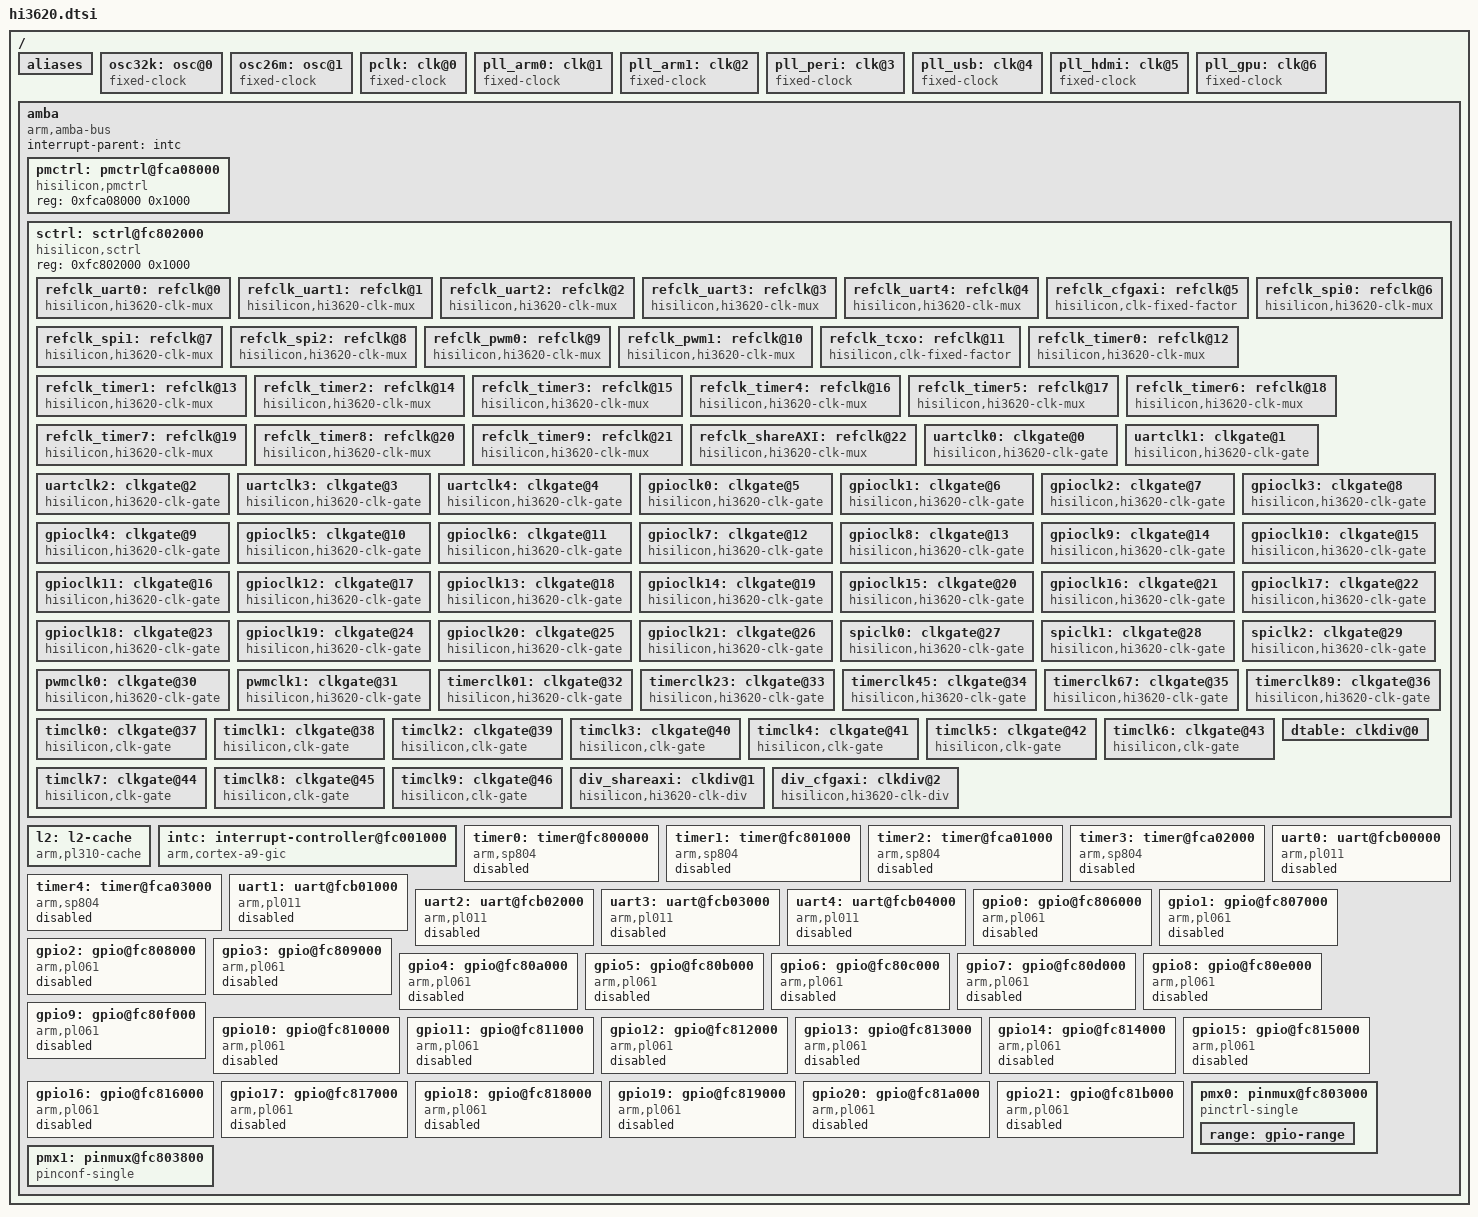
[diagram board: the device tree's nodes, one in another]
/*
 * Hisilicon Ltd. Hi3620 SoC
 *
 * Copyright (C) 2012-2013 Hisilicon Ltd.
 * Copyright (C) 2012-2013 Linaro Ltd.
 *
 * Author: Haojian Zhuang <haojian.zhuang@linaro.org>
 *
 * This program is free software; you can redistribute it and/or modify
 * it under the terms of the GNU General Public License version 2 as
 * publishhed by the Free Software Foundation.
 */

/include/ "skeleton.dtsi"

/ {
	aliases {
		serial0 = &uart0;
		serial1 = &uart1;
		serial2 = &uart2;
		serial3 = &uart3;
		serial4 = &uart4;
	};

	osc32k: osc@0 {
		compatible = "fixed-clock";
		#clock-cells = <0>;
		clock-frequency = <32768>;
		clock-output-names = "osc32khz";
	};
	osc26m: osc@1 {
		compatible = "fixed-clock";
		#clock-cells = <0>;
		clock-frequency = <26000000>;
		clock-output-names = "osc26mhz";
	};
	pclk: clk@0 {
		compatible = "fixed-clock";
		#clock-cells = <0>;
		clock-frequency = <26000000>;
		clock-output-names = "apb_pclk";
	};
	pll_arm0: clk@1 {
		compatible = "fixed-clock";
		#clock-cells = <0>;
		clock-frequency = <1600000000>;
		clock-output-names = "armpll0";
	};
	pll_arm1: clk@2 {
		compatible = "fixed-clock";
		#clock-cells = <0>;
		clock-frequency = <1600000000>;
		clock-output-names = "armpll1";
	};
	pll_peri: clk@3 {
		compatible = "fixed-clock";
		#clock-cells = <0>;
		clock-frequency = <1440000000>;
		clock-output-names = "armpll2";
	};
	pll_usb: clk@4 {
		compatible = "fixed-clock";
		#clock-cells = <0>;
		clock-frequency = <1440000000>;
		clock-output-names = "armpll3";
	};
	pll_hdmi: clk@5 {
		compatible = "fixed-clock";
		#clock-cells = <0>;
		clock-frequency = <1188000000>;
		clock-output-names = "armpll4";
	};
	pll_gpu: clk@6 {
		compatible = "fixed-clock";
		#clock-cells = <0>;
		clock-frequency = <1300000000>;
		clock-output-names = "armpll5";
	};

	amba {
		#address-cells = <1>;
		#size-cells = <1>;
		compatible = "arm,amba-bus";
		interrupt-parent = <&intc>;
		ranges;

		pmctrl: pmctrl@fca08000 {
			compatible = "hisilicon,pmctrl";
			reg = <0xfca08000 0x1000>;
 		};

		sctrl: sctrl@fc802000 {
			compatible = "hisilicon,sctrl";
			reg = <0xfc802000 0x1000>;

			refclk_uart0: refclk@0 {
				compatible = "hisilicon,hi3620-clk-mux";
				#clock-cells = <0>;
				clocks = <&osc26m &pclk>;
				clock-output-names = "rclk_uart0";
				/* each item value */
				/* reg_offset, enable_bits */
				hisilicon,hi3620-clkmux = <0x100 0x80>;
			};
			refclk_uart1: refclk@1 {
				compatible = "hisilicon,hi3620-clk-mux";
				#clock-cells = <0>;
				clocks = <&osc26m &pclk>;
				clock-output-names = "rclk_uart1";
				hisilicon,hi3620-clkmux = <0x100 0x100>;
			};
			refclk_uart2: refclk@2 {
				compatible = "hisilicon,hi3620-clk-mux";
				#clock-cells = <0>;
				clocks = <&osc26m &pclk>;
				clock-output-names = "rclk_uart2";
				hisilicon,hi3620-clkmux = <0x100 0x200>;
			};
			refclk_uart3: refclk@3 {
				compatible = "hisilicon,hi3620-clk-mux";
				#clock-cells = <0>;
				clocks = <&osc26m &pclk>;
				clock-output-names = "rclk_uart3";
				hisilicon,hi3620-clkmux = <0x100 0x400>;
			};
			refclk_uart4: refclk@4 {
				compatible = "hisilicon,hi3620-clk-mux";
				#clock-cells = <0>;
				clocks = <&osc26m &pclk>;
				clock-output-names = "rclk_uart4";
				hisilicon,hi3620-clkmux = <0x100 0x800>;
			};
			refclk_cfgaxi: refclk@5 {
				compatible = "hisilicon,clk-fixed-factor";
				#clock-cells = <0>;
				clocks = <&pll_peri>;
				clock-output-names = "rclk_cfgaxi";
				/*mult, div*/
				hisilicon,fixed-factor = <1 30>;
			};
			refclk_spi0: refclk@6 {
				compatible = "hisilicon,hi3620-clk-mux";
				#clock-cells = <0>;
				clocks = <&osc26m &refclk_cfgaxi>;
				clock-output-names = "rclk_spi0";
				hisilicon,hi3620-clkmux = <0x100 0x1000>;
			};
			refclk_spi1: refclk@7 {
				compatible = "hisilicon,hi3620-clk-mux";
				#clock-cells = <0>;
				clocks = <&osc26m &refclk_cfgaxi>;
				clock-output-names = "rclk_spi1";
				hisilicon,hi3620-clkmux = <0x100 0x2000>;
			};
			refclk_spi2: refclk@8 {
				compatible = "hisilicon,hi3620-clk-mux";
				#clock-cells = <0>;
				clocks = <&osc26m &refclk_cfgaxi>;
				clock-output-names = "rclk_spi2";
				hisilicon,hi3620-clkmux = <0x100 0x4000>;
			};
			refclk_pwm0: refclk@9 {
				compatible = "hisilicon,hi3620-clk-mux";
				#clock-cells = <0>;
				clocks = <&osc32k &osc26m>;
				clock-output-names = "rclk_pwm0";
				hisilicon,hi3620-clkmux = <0x104 0x400>;
			};
			refclk_pwm1: refclk@10 {
				compatible = "hisilicon,hi3620-clk-mux";
				#clock-cells = <0>;
				clocks = <&osc32k &osc26m>;
				clock-output-names = "rclk_pwm1";
				hisilicon,hi3620-clkmux = <0x104 0x800>;
			};
			refclk_tcxo: refclk@11 {
				compatible = "hisilicon,clk-fixed-factor";
				#clock-cells = <0>;
				clocks = <&osc26m>;
				clock-output-names = "rclk_tcxo";
				hisilicon,fixed-factor = <1 4>;
			};
			refclk_timer0: refclk@12 {
				compatible = "hisilicon,hi3620-clk-mux";
				#clock-cells = <0>;
				clocks = <&osc32k &timerclk01>;
				clock-output-names = "rclk_tim0";
				hisilicon,hi3620-clkmux = <0 0x8000>;
			};
			refclk_timer1: refclk@13 {
				compatible = "hisilicon,hi3620-clk-mux";
				#clock-cells = <0>;
				clocks = <&osc32k &timerclk01>;
				clock-output-names = "rclk_tim1";
				hisilicon,hi3620-clkmux = <0 0x20000>;
			};
			refclk_timer2: refclk@14 {
				compatible = "hisilicon,hi3620-clk-mux";
				#clock-cells = <0>;
				clocks = <&osc32k &timerclk23>;
				clock-output-names = "rclk_tim2";
				hisilicon,hi3620-clkmux = <0 0x80000>;
			};
			refclk_timer3: refclk@15 {
				compatible = "hisilicon,hi3620-clk-mux";
				#clock-cells = <0>;
				clocks = <&osc32k &timerclk23>;
				clock-output-names = "rclk_tim3";
				hisilicon,hi3620-clkmux = <0 0x200000>;
			};
			refclk_timer4: refclk@16 {
				compatible = "hisilicon,hi3620-clk-mux";
				#clock-cells = <0>;
				clocks = <&osc32k &timerclk45>;
				clock-output-names = "rclk_tim4";
				hisilicon,hi3620-clkmux = <0x18 0x1>;
			};
			refclk_timer5: refclk@17 {
				compatible = "hisilicon,hi3620-clk-mux";
				#clock-cells = <0>;
				clocks = <&osc32k &timerclk45>;
				clock-output-names = "rclk_tim5";
				hisilicon,hi3620-clkmux = <0x18 0x4>;
			};
			refclk_timer6: refclk@18 {
				compatible = "hisilicon,hi3620-clk-mux";
				#clock-cells = <0>;
				clocks = <&osc32k &timerclk67>;
				clock-output-names = "rclk_tim6";
				hisilicon,hi3620-clkmux = <0x18 0x10>;
			};
			refclk_timer7: refclk@19 {
				compatible = "hisilicon,hi3620-clk-mux";
				#clock-cells = <0>;
				clocks = <&osc32k &timerclk67>;
				clock-output-names = "rclk_tim7";
				hisilicon,hi3620-clkmux = <0x18 0x40>;
			};
			refclk_timer8: refclk@20 {
				compatible = "hisilicon,hi3620-clk-mux";
				#clock-cells = <0>;
				clocks = <&osc32k &timerclk89>;
				clock-output-names = "rclk_tim8";
				hisilicon,hi3620-clkmux = <0x18 0x100>;
			};
			refclk_timer9: refclk@21 {
				compatible = "hisilicon,hi3620-clk-mux";
				#clock-cells = <0>;
				clocks = <&osc32k &timerclk89>;
				clock-output-names = "rclk_tim9";
				hisilicon,hi3620-clkmux = <0x18 0x400>;
			};
			refclk_shareAXI: refclk@22 {
				compatible = "hisilicon,hi3620-clk-mux";
				#clock-cells = <0>;
				clocks = <&pll_usb &pll_peri>;
				clock-output-names = "rclk_shareAXI";
				hisilicon,hi3620-clkmux = <0x24 0x8000>;
			};
			uartclk0: clkgate@0 {
				compatible = "hisilicon,hi3620-clk-gate";
				#clock-cells = <0>;
				clocks = <&refclk_uart0>;
				clock-output-names = "uartclk0";
				hisilicon,hi3620-clkreset = <0x98 0x10000>;
				hisilicon,hi3620-clkgate = <0x40 0x10000>;
			};
			uartclk1: clkgate@1 {
				compatible = "hisilicon,hi3620-clk-gate";
				#clock-cells = <0>;
				clocks = <&refclk_uart1>;
				clock-output-names = "uartclk1";
				hisilicon,hi3620-clkreset = <0x98 0x20000>;
				hisilicon,hi3620-clkgate = <0x40 0x20000>;
			};
			uartclk2: clkgate@2 {
				compatible = "hisilicon,hi3620-clk-gate";
				#clock-cells = <0>;
				clocks = <&refclk_uart2>;
				clock-output-names = "uartclk2";
				hisilicon,hi3620-clkreset = <0x98 0x40000>;
				hisilicon,hi3620-clkgate = <0x40 0x40000>;
			};
			uartclk3: clkgate@3 {
				compatible = "hisilicon,hi3620-clk-gate";
				#clock-cells = <0>;
				clocks = <&refclk_uart3>;
				clock-output-names = "uartclk3";
				hisilicon,hi3620-clkreset = <0x98 0x80000>;
				hisilicon,hi3620-clkgate = <0x40 0x80000>;
			};
			uartclk4: clkgate@4 {
				compatible = "hisilicon,hi3620-clk-gate";
				#clock-cells = <0>;
				clocks = <&refclk_uart4>;
				clock-output-names = "uartclk4";
				hisilicon,hi3620-clkreset = <0x98 0x100000>;
				hisilicon,hi3620-clkgate = <0x40 0x100000>;
			};
			gpioclk0: clkgate@5 {
				compatible = "hisilicon,hi3620-clk-gate";
				#clock-cells = <0>;
				clocks = <&pclk>;
				clock-output-names = "gpioclk0";
				hisilicon,hi3620-clkreset = <0x80 0x100>;
				hisilicon,hi3620-clkgate = <0x20 0x100>;
			};
			gpioclk1: clkgate@6 {
				compatible = "hisilicon,hi3620-clk-gate";
				#clock-cells = <0>;
				clocks = <&pclk>;
				clock-output-names = "gpioclk1";
				hisilicon,hi3620-clkreset = <0x80 0x200>;
				hisilicon,hi3620-clkgate = <0x20 0x200>;
			};
			gpioclk2: clkgate@7 {
				compatible = "hisilicon,hi3620-clk-gate";
				#clock-cells = <0>;
				clocks = <&pclk>;
				clock-output-names = "gpioclk2";
				hisilicon,hi3620-clkreset = <0x80 0x400>;
				hisilicon,hi3620-clkgate = <0x20 0x400>;
			};
			gpioclk3: clkgate@8 {
				compatible = "hisilicon,hi3620-clk-gate";
				#clock-cells = <0>;
				clocks = <&pclk>;
				clock-output-names = "gpioclk3";
				hisilicon,hi3620-clkreset = <0x80 0x800>;
				hisilicon,hi3620-clkgate = <0x20 0x800>;
			};
			gpioclk4: clkgate@9 {
				compatible = "hisilicon,hi3620-clk-gate";
				#clock-cells = <0>;
				clocks = <&pclk>;
				clock-output-names = "gpioclk4";
				hisilicon,hi3620-clkreset = <0x80 0x1000>;
				hisilicon,hi3620-clkgate = <0x20 0x1000>;
			};
			gpioclk5: clkgate@10 {
				compatible = "hisilicon,hi3620-clk-gate";
				#clock-cells = <0>;
				clocks = <&pclk>;
				clock-output-names = "gpioclk5";
				hisilicon,hi3620-clkreset = <0x80 0x2000>;
				hisilicon,hi3620-clkgate = <0x20 0x2000>;
			};
			gpioclk6: clkgate@11 {
				compatible = "hisilicon,hi3620-clk-gate";
				#clock-cells = <0>;
				clocks = <&pclk>;
				clock-output-names = "gpioclk6";
				hisilicon,hi3620-clkreset = <0x80 0x4000>;
				hisilicon,hi3620-clkgate = <0x20 0x4000>;
			};
			gpioclk7: clkgate@12 {
				compatible = "hisilicon,hi3620-clk-gate";
				#clock-cells = <0>;
				clocks = <&pclk>;
				clock-output-names = "gpioclk7";
				hisilicon,hi3620-clkreset = <0x80 0x8000>;
				hisilicon,hi3620-clkgate = <0x20 0x8000>;
			};
			gpioclk8: clkgate@13 {
				compatible = "hisilicon,hi3620-clk-gate";
				#clock-cells = <0>;
				clocks = <&pclk>;
				clock-output-names = "gpioclk8";
				hisilicon,hi3620-clkreset = <0x80 0x10000>;
				hisilicon,hi3620-clkgate = <0x20 0x10000>;
			};
			gpioclk9: clkgate@14 {
				compatible = "hisilicon,hi3620-clk-gate";
				#clock-cells = <0>;
				clocks = <&pclk>;
				clock-output-names = "gpioclk9";
				hisilicon,hi3620-clkreset = <0x80 0x20000>;
				hisilicon,hi3620-clkgate = <0x20 0x20000>;
			};
			gpioclk10: clkgate@15 {
				compatible = "hisilicon,hi3620-clk-gate";
				#clock-cells = <0>;
				clocks = <&pclk>;
				clock-output-names = "gpioclk10";
				hisilicon,hi3620-clkreset = <0x80 0x40000>;
				hisilicon,hi3620-clkgate = <0x20 0x40000>;
			};
			gpioclk11: clkgate@16 {
				compatible = "hisilicon,hi3620-clk-gate";
				#clock-cells = <0>;
				clocks = <&pclk>;
				clock-output-names = "gpioclk11";
				hisilicon,hi3620-clkreset = <0x80 0x80000>;
				hisilicon,hi3620-clkgate = <0x20 0x80000>;
			};
			gpioclk12: clkgate@17 {
				compatible = "hisilicon,hi3620-clk-gate";
				#clock-cells = <0>;
				clocks = <&pclk>;
				clock-output-names = "gpioclk12";
				hisilicon,hi3620-clkreset = <0x80 0x100000>;
				hisilicon,hi3620-clkgate = <0x20 0x100000>;
			};
			gpioclk13: clkgate@18 {
				compatible = "hisilicon,hi3620-clk-gate";
				#clock-cells = <0>;
				clocks = <&pclk>;
				clock-output-names = "gpioclk13";
				hisilicon,hi3620-clkreset = <0x80 0x200000>;
				hisilicon,hi3620-clkgate = <0x20 0x200000>;
			};
			gpioclk14: clkgate@19 {
				compatible = "hisilicon,hi3620-clk-gate";
				#clock-cells = <0>;
				clocks = <&pclk>;
				clock-output-names = "gpioclk14";
				hisilicon,hi3620-clkreset = <0x80 0x400000>;
				hisilicon,hi3620-clkgate = <0x20 0x400000>;
			};
			gpioclk15: clkgate@20 {
				compatible = "hisilicon,hi3620-clk-gate";
				#clock-cells = <0>;
				clocks = <&pclk>;
				clock-output-names = "gpioclk15";
				hisilicon,hi3620-clkreset = <0x80 0x800000>;
				hisilicon,hi3620-clkgate = <0x20 0x800000>;
			};
			gpioclk16: clkgate@21 {
				compatible = "hisilicon,hi3620-clk-gate";
				#clock-cells = <0>;
				clocks = <&pclk>;
				clock-output-names = "gpioclk16";
				hisilicon,hi3620-clkreset = <0x80 0x1000000>;
				hisilicon,hi3620-clkgate = <0x20 0x1000000>;
			};
			gpioclk17: clkgate@22 {
				compatible = "hisilicon,hi3620-clk-gate";
				#clock-cells = <0>;
				clocks = <&pclk>;
				clock-output-names = "gpioclk17";
				hisilicon,hi3620-clkreset = <0x80 0x2000000>;
				hisilicon,hi3620-clkgate = <0x20 0x2000000>;
			};
			gpioclk18: clkgate@23 {
				compatible = "hisilicon,hi3620-clk-gate";
				#clock-cells = <0>;
				clocks = <&pclk>;
				clock-output-names = "gpioclk18";
				hisilicon,hi3620-clkreset = <0x80 0x4000000>;
				hisilicon,hi3620-clkgate = <0x20 0x4000000>;
			};
			gpioclk19: clkgate@24 {
				compatible = "hisilicon,hi3620-clk-gate";
				#clock-cells = <0>;
				clocks = <&pclk>;
				clock-output-names = "gpioclk19";
				hisilicon,hi3620-clkreset = <0x80 0x8000000>;
				hisilicon,hi3620-clkgate = <0x20 0x8000000>;
			};
			gpioclk20: clkgate@25 {
				compatible = "hisilicon,hi3620-clk-gate";
				#clock-cells = <0>;
				clocks = <&pclk>;
				clock-output-names = "gpioclk20";
				hisilicon,hi3620-clkreset = <0x80 0x10000000>;
				hisilicon,hi3620-clkgate = <0x20 0x10000000>;
			};
			gpioclk21: clkgate@26 {
				compatible = "hisilicon,hi3620-clk-gate";
				#clock-cells = <0>;
				clocks = <&pclk>;
				clock-output-names = "gpioclk21";
				hisilicon,hi3620-clkreset = <0x80 0x20000000>;
				hisilicon,hi3620-clkgate = <0x20 0x20000000>;
			};
			spiclk0: clkgate@27 {
				compatible = "hisilicon,hi3620-clk-gate";
				#clock-cells = <0>;
				clocks = <&refclk_spi0>;
				clock-output-names = "spiclk0";
				hisilicon,hi3620-clkreset = <0x98 0x200000>;
				hisilicon,hi3620-clkgate = <0x40 0x200000>;
			};
			spiclk1: clkgate@28 {
				compatible = "hisilicon,hi3620-clk-gate";
				#clock-cells = <0>;
				clocks = <&refclk_spi1>;
				clock-output-names = "spiclk1";
				hisilicon,hi3620-clkreset = <0x98 0x400000>;
				hisilicon,hi3620-clkgate = <0x40 0x400000>;
			};
			spiclk2: clkgate@29 {
				compatible = "hisilicon,hi3620-clk-gate";
				#clock-cells = <0>;
				clocks = <&refclk_spi2>;
				clock-output-names = "spiclk2";
				hisilicon,hi3620-clkreset = <0x98 0x800000>;
				hisilicon,hi3620-clkgate = <0x40 0x800000>;
			};
			pwmclk0: clkgate@30 {
				compatible = "hisilicon,hi3620-clk-gate";
				#clock-cells = <0>;
				clocks = <&refclk_pwm0>;
				clock-output-names = "pwmclk0";
				hisilicon,hi3620-clkreset = <0x98 0x80>;
				hisilicon,hi3620-clkgate = <0x40 0x80>;
			};
			pwmclk1: clkgate@31 {
				compatible = "hisilicon,hi3620-clk-gate";
				#clock-cells = <0>;
				clocks = <&refclk_pwm1>;
				clock-output-names = "pwmclk1";
				hisilicon,hi3620-clkreset = <0x98 0x100>;
				hisilicon,hi3620-clkgate = <0x40 0x100>;
			};
			timerclk01: clkgate@32 {
				compatible = "hisilicon,hi3620-clk-gate";
				#clock-cells = <0>;
				clocks = <&refclk_tcxo>;
				clock-output-names = "timerclk01";
				hisilicon,hi3620-clkreset = <0x80 0x1>;
				hisilicon,hi3620-clkgate = <0x20 0x3>;
			};
			timerclk23: clkgate@33 {
				compatible = "hisilicon,hi3620-clk-gate";
				#clock-cells = <0>;
				clocks = <&refclk_tcxo>;
				clock-output-names = "timerclk23";
				hisilicon,hi3620-clkreset = <0x80 0x2>;
				hisilicon,hi3620-clkgate = <0x20 0xc>;
			};
			timerclk45: clkgate@34 {
				compatible = "hisilicon,hi3620-clk-gate";
				#clock-cells = <0>;
				clocks = <&refclk_tcxo>;
				clock-output-names = "timerclk45";
				hisilicon,hi3620-clkreset = <0x98 0x8>;
				hisilicon,hi3620-clkgate = <0x40 0x8>;
			};
			timerclk67: clkgate@35 {
				compatible = "hisilicon,hi3620-clk-gate";
				#clock-cells = <0>;
				clocks = <&refclk_tcxo>;
				clock-output-names = "timerclk67";
				hisilicon,hi3620-clkreset = <0x98 0x10>;
				hisilicon,hi3620-clkgate = <0x40 0x10>;
			};
			timerclk89: clkgate@36 {
				compatible = "hisilicon,hi3620-clk-gate";
				#clock-cells = <0>;
				clocks = <&refclk_tcxo>;
				clock-output-names = "timerclk89";
				hisilicon,hi3620-clkreset = <0x98 0x20>;
				hisilicon,hi3620-clkgate = <0x40 0x20>;
			};
			timclk0: clkgate@37 {
				compatible = "hisilicon,clk-gate";
				#clock-cells = <0>;
				clocks = <&refclk_timer0>;
				clock-output-names = "timclk0";
				hisilicon,clkgate-inverted;
				hisilicon,clkgate = <0 16>;
			};
			timclk1: clkgate@38 {
				compatible = "hisilicon,clk-gate";
				#clock-cells = <0>;
				clocks = <&refclk_timer1>;
				clock-output-names = "timclk1";
				hisilicon,clkgate-inverted;
				hisilicon,clkgate = <0 18>;
			};
			timclk2: clkgate@39 {
				compatible = "hisilicon,clk-gate";
				#clock-cells = <0>;
				clocks = <&refclk_timer2>;
				clock-output-names = "timclk2";
				hisilicon,clkgate-inverted;
				hisilicon,clkgate = <0 20>;
			};
			timclk3: clkgate@40 {
				compatible = "hisilicon,clk-gate";
				#clock-cells = <0>;
				clocks = <&refclk_timer3>;
				clock-output-names = "timclk3";
				hisilicon,clkgate-inverted;
				hisilicon,clkgate = <0 22>;
			};
			timclk4: clkgate@41 {
				compatible = "hisilicon,clk-gate";
				#clock-cells = <0>;
				clocks = <&refclk_timer4>;
				clock-output-names = "timclk4";
				hisilicon,clkgate-inverted;
				hisilicon,clkgate = <0x18 0>;
			};
			timclk5: clkgate@42 {
				compatible = "hisilicon,clk-gate";
				#clock-cells = <0>;
				clocks = <&refclk_timer5>;
				clock-output-names = "timclk5";
				hisilicon,clkgate-inverted;
				hisilicon,clkgate = <0x18 2>;
			};
			timclk6: clkgate@43 {
				compatible = "hisilicon,clk-gate";
				#clock-cells = <0>;
				clocks = <&refclk_timer6>;
				clock-output-names = "timclk6";
				hisilicon,clkgate-inverted;
				hisilicon,clkgate = <0x18 4>;
			};
			timclk7: clkgate@44 {
				compatible = "hisilicon,clk-gate";
				#clock-cells = <0>;
				clocks = <&refclk_timer7>;
				clock-output-names = "timclk7";
				hisilicon,clkgate-inverted;
				hisilicon,clkgate = <0x18 6>;
			};
			timclk8: clkgate@45 {
				compatible = "hisilicon,clk-gate";
				#clock-cells = <0>;
				clocks = <&refclk_timer8>;
				clock-output-names = "timclk8";
				hisilicon,clkgate-inverted;
				hisilicon,clkgate = <0x18 8>;
			};
			timclk9: clkgate@46 {
				compatible = "hisilicon,clk-gate";
				#clock-cells = <0>;
				clocks = <&refclk_timer9>;
				clock-output-names = "timclk9";
				hisilicon,clkgate-inverted;
				hisilicon,clkgate = <0x18 10>;
			};
			dtable: clkdiv@0 {
				#hisilicon,clkdiv-table-cells = <2>;
			};
			div_shareaxi: clkdiv@1 {
				compatible = "hisilicon,hi3620-clk-div";
				#clock-cells = <0>;
				clocks = <&refclk_shareAXI>;
				clock-output-names = "shareAXI_div";
				hisilicon,clkdiv-table = <
					&dtable 0 1 &dtable 1 2 &dtable 2 3 &dtable 3 4
					&dtable 4 5 &dtable 5 6 &dtable 6 7 &dtable 7 8
					&dtable 8 9 &dtable 9 10 &dtable 10 11 &dtable 11 12
					&dtable 12 13 &dtable 13 14 &dtable 14 15 &dtable 15 16
					&dtable 16 17 &dtable 17 18 &dtable 18 19 &dtable 19 20
					&dtable 20 21 &dtable 21 22 &dtable 22 23 &dtable 23 24
					&dtable 24 25 &dtable 25 26 &dtable 26 27 &dtable 27 28
					&dtable 28 29 &dtable 29 30 &dtable 30 31 &dtable 31 32>;
				/* divider register offset, mask */
				hisilicon,clkdiv = <0x100 0x1f>;
			};
			div_cfgaxi: clkdiv@2 {
				compatible = "hisilicon,hi3620-clk-div";
				#clock-cells = <0>;
				clocks = <&div_shareaxi>;
				clock-output-names = "cfgAXI_div";
				hisilicon,clkdiv-table = <&dtable 0x01 2>;
				hisilicon,clkdiv = <0x100 0x60>;
			};
 		};

		l2: l2-cache {
			compatible = "arm,pl310-cache";
			reg = <0xfc10000 0x100000>;
			interrupts = <0 15 4>;
			cache-unified;
			cache-level = <2>;
		};

		intc: interrupt-controller@fc001000 {
			compatible = "arm,cortex-a9-gic";
			#interrupt-cells = <3>;
			#address-cells = <0>;
			interrupt-controller;
			/* gic dist base, gic cpu base */
			reg = <0xfc001000 0x1000>, <0xfc000100 0x100>;
		};

		timer0: timer@fc800000 {
			compatible = "arm,sp804", "arm,primecell";
			reg = <0xfc800000 0x1000>;
			/* timer00 & timer01 */
			interrupts = <0 0 4>, <0 1 4>;
			clocks = <&timclk0 &timclk1>;
			clock-names = "apb_pclk";
			status = "disabled";
		};

		timer1: timer@fc801000 {
			compatible = "arm,sp804", "arm,primecell";
			reg = <0xfc801000 0x1000>;
			/* timer10 & timer11 */
			interrupts = <0 2 4>, <0 3 4>;
			clocks = <&timclk2 &timclk3>;
			clock-names = "apb_pclk";
			status = "disabled";
		};

		timer2: timer@fca01000 {
			compatible = "arm,sp804", "arm,primecell";
			reg = <0xfca01000 0x1000>;
			/* timer20 & timer21 */
			interrupts = <0 4 4>, <0 5 4>;
			clocks = <&timclk4 &timclk5>;
			clock-names = "apb_pclk";
			status = "disabled";
		};

		timer3: timer@fca02000 {
			compatible = "arm,sp804", "arm,primecell";
			reg = <0xfca02000 0x1000>;
			/* timer30 & timer31 */
			interrupts = <0 6 4>, <0 7 4>;
			clocks = <&timclk6 &timclk7>;
			clock-names = "apb_pclk";
			status = "disabled";
		};

		timer4: timer@fca03000 {
			compatible = "arm,sp804", "arm,primecell";
			reg = <0xfca03000 0x1000>;
			/* timer40 & timer41 */
			interrupts = <0 96 4>, <0 97 4>;
			clocks = <&timclk8 &timclk9>;
			clock-names = "apb_pclk";
			status = "disabled";
		};

		uart0: uart@fcb00000 {
			compatible = "arm,pl011", "arm,primecell";
			reg = <0xfcb00000 0x1000>;
			interrupts = <0 20 4>;
			clocks = <&uartclk0>;
			clock-names = "apb_pclk";
			status = "disabled";
		};

		uart1: uart@fcb01000 {
			compatible = "arm,pl011", "arm,primecell";
			reg = <0xfcb01000 0x1000>;
			interrupts = <0 21 4>;
			clocks = <&uartclk1>;
			clock-names = "apb_pclk";
			status = "disabled";
		};

		uart2: uart@fcb02000 {
			compatible = "arm,pl011", "arm,primecell";
			reg = <0xfcb02000 0x1000>;
			interrupts = <0 22 4>;
			clocks = <&uartclk2>;
			clock-names = "apb_pclk";
			status = "disabled";
		};

		uart3: uart@fcb03000 {
			compatible = "arm,pl011", "arm,primecell";
			reg = <0xfcb03000 0x1000>;
			interrupts = <0 23 4>;
			clocks = <&uartclk3>;
			clock-names = "apb_pclk";
			status = "disabled";
		};

		uart4: uart@fcb04000 {
			compatible = "arm,pl011", "arm,primecell";
			reg = <0xfcb04000 0x1000>;
			interrupts = <0 24 4>;
			clocks = <&uartclk4>;
			clock-names = "apb_pclk";
			status = "disabled";
		};

		gpio0: gpio@fc806000 {
			compatible = "arm,pl061", "arm,primecell";
			reg = <0xfc806000 0x1000>;
			interrupts = <0 64 0x4>;
			gpio-controller;
			#gpio-cells = <2>;
			gpio-ranges = <	&pmx0 2 0 1 &pmx0 3 0 1 &pmx0 4 0 1
					&pmx0 5 0 1 &pmx0 6 1 1 &pmx0 7 2 1>;
			interrupt-controller;
			#interrupt-cells = <2>;
			clocks = <&gpioclk0>;
			clock-names = "apb_pclk";
			status = "disable";
		};

		gpio1: gpio@fc807000 {
			compatible = "arm,pl061", "arm,primecell";
			reg = <0xfc807000 0x1000>;
			interrupts = <0 65 0x4>;
			gpio-controller;
			#gpio-cells = <2>;
			gpio-ranges = <	&pmx0 0 3 1 &pmx0 1 3 1 &pmx0 2 3 1
					&pmx0 3 3 1 &pmx0 4 3 1 &pmx0 5 4 1
					&pmx0 6 5 1 &pmx0 7 6 1>;
			interrupt-controller;
			#interrupt-cells = <2>;
			clocks = <&gpioclk1>;
			clock-names = "apb_pclk";
			status = "disable";
		};

		gpio2: gpio@fc808000 {
			compatible = "arm,pl061", "arm,primecell";
			reg = <0xfc808000 0x1000>;
			interrupts = <0 66 0x4>;
			gpio-controller;
			#gpio-cells = <2>;
			gpio-ranges = <	&pmx0 0 7 1 &pmx0 1 8 1 &pmx0 2 9 1
					&pmx0 3 10 1 &pmx0 4 3 1 &pmx0 5 3 1
					&pmx0 6 3 1 &pmx0 7 3 1>;
			interrupt-controller;
			#interrupt-cells = <2>;
			clocks = <&gpioclk2>;
			clock-names = "apb_pclk";
			status = "disable";
		};

		gpio3: gpio@fc809000 {
			compatible = "arm,pl061", "arm,primecell";
			reg = <0xfc809000 0x1000>;
			interrupts = <0 67 0x4>;
			gpio-controller;
			#gpio-cells = <2>;
			gpio-ranges = <	&pmx0 0 3 1 &pmx0 1 3 1 &pmx0 2 3 1
					&pmx0 3 3 1 &pmx0 4 11 1 &pmx0 5 11 1
					&pmx0 6 11 1 &pmx0 7 11 1>;
			interrupt-controller;
			#interrupt-cells = <2>;
			clocks = <&gpioclk3>;
			clock-names = "apb_pclk";
			status = "disable";
		};

		gpio4: gpio@fc80a000 {
			compatible = "arm,pl061", "arm,primecell";
			reg = <0xfc80a000 0x1000>;
			interrupts = <0 68 0x4>;
			gpio-controller;
			#gpio-cells = <2>;
			gpio-ranges = <	&pmx0 0 11 1 &pmx0 1 11 1 &pmx0 2 11 1
					&pmx0 3 11 1 &pmx0 4 12 1 &pmx0 5 12 1
					&pmx0 6 13 1 &pmx0 7 13 1>;
			interrupt-controller;
			#interrupt-cells = <2>;
			clocks = <&gpioclk4>;
			clock-names = "apb_pclk";
			status = "disable";
		};

		gpio5: gpio@fc80b000 {
			compatible = "arm,pl061", "arm,primecell";
			reg = <0xfc80b000 0x1000>;
			interrupts = <0 69 0x4>;
			gpio-controller;
			#gpio-cells = <2>;
			gpio-ranges = <	&pmx0 0 14 1 &pmx0 1 15 1 &pmx0 2 16 1
					&pmx0 3 16 1 &pmx0 4 16 1 &pmx0 5 16 1
					&pmx0 6 16 1 &pmx0 7 16 1>;
			interrupt-controller;
			#interrupt-cells = <2>;
			clocks = <&gpioclk5>;
			clock-names = "apb_pclk";
			status = "disable";
		};

		gpio6: gpio@fc80c000 {
			compatible = "arm,pl061", "arm,primecell";
			reg = <0xfc80c000 0x1000>;
			interrupts = <0 70 0x4>;
			gpio-controller;
			#gpio-cells = <2>;
			gpio-ranges = <	&pmx0 0 16 1 &pmx0 1 16 1 &pmx0 2 17 1
					&pmx0 3 17 1 &pmx0 4 18 1 &pmx0 5 18 1
					&pmx0 6 18 1 &pmx0 7 19 1>;
			interrupt-controller;
			#interrupt-cells = <2>;
			clocks = <&gpioclk6>;
			clock-names = "apb_pclk";
			status = "disable";
		};

		gpio7: gpio@fc80d000 {
			compatible = "arm,pl061", "arm,primecell";
			reg = <0xfc80d000 0x1000>;
			interrupts = <0 71 0x4>;
			gpio-controller;
			#gpio-cells = <2>;
			gpio-ranges = <	&pmx0 0 19 1 &pmx0 1 20 1 &pmx0 2 21 1
					&pmx0 3 22 1 &pmx0 4 23 1 &pmx0 5 24 1
					&pmx0 6 25 1 &pmx0 7 26 1>;
			interrupt-controller;
			#interrupt-cells = <2>;
			clocks = <&gpioclk7>;
			clock-names = "apb_pclk";
			status = "disable";
		};

		gpio8: gpio@fc80e000 {
			compatible = "arm,pl061", "arm,primecell";
			reg = <0xfc80e000 0x1000>;
			interrupts = <0 72 0x4>;
			gpio-controller;
			#gpio-cells = <2>;
			gpio-ranges = <	&pmx0 0 27 1 &pmx0 1 28 1 &pmx0 2 29 1
					&pmx0 3 30 1 &pmx0 4 31 1 &pmx0 5 32 1
					&pmx0 6 33 1 &pmx0 7 34 1>;
			interrupt-controller;
			#interrupt-cells = <2>;
			clocks = <&gpioclk8>;
			clock-names = "apb_pclk";
			status = "disable";
		};

		gpio9: gpio@fc80f000 {
			compatible = "arm,pl061", "arm,primecell";
			reg = <0xfc80f000 0x1000>;
			interrupts = <0 73 0x4>;
			gpio-controller;
			#gpio-cells = <2>;
			gpio-ranges = <	&pmx0 0 35 1 &pmx0 1 36 1 &pmx0 2 37 1
					&pmx0 3 38 1 &pmx0 4 39 1 &pmx0 5 40 1
					&pmx0 6 41 1>;
			interrupt-controller;
			#interrupt-cells = <2>;
			clocks = <&gpioclk9>;
			clock-names = "apb_pclk";
			status = "disable";
		};

		gpio10: gpio@fc810000 {
			compatible = "arm,pl061", "arm,primecell";
			reg = <0xfc810000 0x1000>;
			interrupts = <0 74 0x4>;
			gpio-controller;
			#gpio-cells = <2>;
			gpio-ranges = <	&pmx0 2 43 1 &pmx0 3 44 1 &pmx0 4 45 1
					&pmx0 5 45 1 &pmx0 6 46 1 &pmx0 7 46 1>;
			interrupt-controller;
			#interrupt-cells = <2>;
			clocks = <&gpioclk10>;
			clock-names = "apb_pclk";
			status = "disable";
		};

		gpio11: gpio@fc811000 {
			compatible = "arm,pl061", "arm,primecell";
			reg = <0xfc811000 0x1000>;
			interrupts = <0 75 0x4>;
			gpio-controller;
			#gpio-cells = <2>;
			gpio-ranges = <	&pmx0 0 47 1 &pmx0 1 47 1 &pmx0 2 47 1
					&pmx0 3 47 1 &pmx0 4 47 1 &pmx0 5 48 1
					&pmx0 6 49 1 &pmx0 7 49 1>;
			interrupt-controller;
			#interrupt-cells = <2>;
			clocks = <&gpioclk11>;
			clock-names = "apb_pclk";
			status = "disable";
		};

		gpio12: gpio@fc812000 {
			compatible = "arm,pl061", "arm,primecell";
			reg = <0xfc812000 0x1000>;
			interrupts = <0 76 0x4>;
			gpio-controller;
			#gpio-cells = <2>;
			gpio-ranges = <	&pmx0 0 49 1 &pmx0 1 50 1 &pmx0 2 49 1
					&pmx0 3 49 1 &pmx0 4 51 1 &pmx0 5 51 1
					&pmx0 6 51 1 &pmx0 7 52 1>;
			interrupt-controller;
			#interrupt-cells = <2>;
			clocks = <&gpioclk12>;
			clock-names = "apb_pclk";
			status = "disable";
		};

		gpio13: gpio@fc813000 {
			compatible = "arm,pl061", "arm,primecell";
			reg = <0xfc813000 0x1000>;
			interrupts = <0 77 0x4>;
			gpio-controller;
			#gpio-cells = <2>;
			gpio-ranges = <	&pmx0 0 51 1 &pmx0 1 51 1 &pmx0 2 53 1
					&pmx0 3 53 1 &pmx0 4 53 1 &pmx0 5 54 1
					&pmx0 6 55 1 &pmx0 7 56 1>;
			interrupt-controller;
			#interrupt-cells = <2>;
			clocks = <&gpioclk13>;
			clock-names = "apb_pclk";
			status = "disable";
		};

		gpio14: gpio@fc814000 {
			compatible = "arm,pl061", "arm,primecell";
			reg = <0xfc814000 0x1000>;
			interrupts = <0 78 0x4>;
			gpio-controller;
			#gpio-cells = <2>;
			gpio-ranges = <	&pmx0 0 57 1 &pmx0 1 97 1 &pmx0 2 97 1
					&pmx0 3 58 1 &pmx0 4 59 1 &pmx0 5 60 1
					&pmx0 6 60 1 &pmx0 7 61 1>;
			interrupt-controller;
			#interrupt-cells = <2>;
			clocks = <&gpioclk14>;
			clock-names = "apb_pclk";
			status = "disable";
		};

		gpio15: gpio@fc815000 {
			compatible = "arm,pl061", "arm,primecell";
			reg = <0xfc815000 0x1000>;
			interrupts = <0 79 0x4>;
			gpio-controller;
			#gpio-cells = <2>;
			gpio-ranges = <	&pmx0 0 61 1 &pmx0 1 62 1 &pmx0 2 62 1
					&pmx0 3 63 1 &pmx0 4 63 1 &pmx0 5 64 1
					&pmx0 6 64 1 &pmx0 7 65 1>;
			interrupt-controller;
			#interrupt-cells = <2>;
			clocks = <&gpioclk15>;
			clock-names = "apb_pclk";
			status = "disable";
		};

		gpio16: gpio@fc816000 {
			compatible = "arm,pl061", "arm,primecell";
			reg = <0xfc816000 0x1000>;
			interrupts = <0 80 0x4>;
			gpio-controller;
			#gpio-cells = <2>;
			gpio-ranges = <	&pmx0 0 66 1 &pmx0 1 67 1 &pmx0 2 68 1
					&pmx0 3 69 1 &pmx0 4 70 1 &pmx0 5 71 1
					&pmx0 6 72 1 &pmx0 7 73 1>;
			interrupt-controller;
			#interrupt-cells = <2>;
			clocks = <&gpioclk16>;
			clock-names = "apb_pclk";
			status = "disable";
		};

		gpio17: gpio@fc817000 {
			compatible = "arm,pl061", "arm,primecell";
			reg = <0xfc817000 0x1000>;
			interrupts = <0 81 0x4>;
			gpio-controller;
			#gpio-cells = <2>;
			gpio-ranges = <	&pmx0 0 74 1 &pmx0 1 75 1 &pmx0 2 76 1
					&pmx0 3 77 1 &pmx0 4 78 1 &pmx0 5 79 1
					&pmx0 6 80 1 &pmx0 7 81 1>;
			interrupt-controller;
			#interrupt-cells = <2>;
			clocks = <&gpioclk17>;
			clock-names = "apb_pclk";
			status = "disable";
		};

		gpio18: gpio@fc818000 {
			compatible = "arm,pl061", "arm,primecell";
			reg = <0xfc818000 0x1000>;
			interrupts = <0 82 0x4>;
			gpio-controller;
			#gpio-cells = <2>;
			gpio-ranges = <	&pmx0 0 82 1 &pmx0 1 83 1 &pmx0 2 83 1
					&pmx0 3 84 1 &pmx0 4 84 1 &pmx0 5 85 1
					&pmx0 6 86 1 &pmx0 7 87 1>;
			interrupt-controller;
			#interrupt-cells = <2>;
			clocks = <&gpioclk18>;
			clock-names = "apb_pclk";
			status = "disable";
		};

		gpio19: gpio@fc819000 {
			compatible = "arm,pl061", "arm,primecell";
			reg = <0xfc819000 0x1000>;
			interrupts = <0 83 0x4>;
			gpio-controller;
			#gpio-cells = <2>;
			gpio-ranges = <	&pmx0 0 87 1 &pmx0 1 87 1 &pmx0 2 88 1
					&pmx0 3 88 1>;
			interrupt-controller;
			#interrupt-cells = <2>;
			clocks = <&gpioclk19>;
			clock-names = "apb_pclk";
			status = "disable";
		};

		gpio20: gpio@fc81a000 {
			compatible = "arm,pl061", "arm,primecell";
			reg = <0xfc81a000 0x1000>;
			interrupts = <0 84 0x4>;
			gpio-controller;
			#gpio-cells = <2>;
			gpio-ranges = <	&pmx0 0 89 1 &pmx0 1 89 1 &pmx0 2 90 1
					&pmx0 3 90 1 &pmx0 4 91 1 &pmx0 5 92 1>;
			interrupt-controller;
			#interrupt-cells = <2>;
			clocks = <&gpioclk20>;
			clock-names = "apb_pclk";
			status = "disable";
		};

		gpio21: gpio@fc81b000 {
			compatible = "arm,pl061", "arm,primecell";
			reg = <0xfc81b000 0x1000>;
			interrupts = <0 85 0x4>;
			gpio-controller;
			#gpio-cells = <2>;
			gpio-ranges = <	&pmx0 3 94 1 &pmx0 7 96 1>;
			interrupt-controller;
			#interrupt-cells = <2>;
			clocks = <&gpioclk21>;
			clock-names = "apb_pclk";
			status = "disable";
		};

		pmx0: pinmux@fc803000 {
			compatible = "pinctrl-single";
			reg = <0xfc803000 0x188>;
			#address-cells = <1>;
			#size-cells = <1>;
			#gpio-range-cells = <3>;
			ranges;

			pinctrl-single,register-width = <32>;
			pinctrl-single,function-mask = <7>;
			/* pin base, nr pins & gpio function */
			pinctrl-single,gpio-range = <&range 0 3 0 &range 3 9 1
						&range 12 1 0 &range 13 29 1
						&range 43 1 0 &range 44 49 1
						&range 94 1 1 &range 96 2 1>;

			range: gpio-range {
				#pinctrl-single,gpio-range-cells = <3>;
			};
		};

		pmx1: pinmux@fc803800 {
			compatible = "pinconf-single";
			reg = <0xfc803800 0x2dc>;
			#address-cells = <1>;
			#size-cells = <1>;
			ranges;

			pinctrl-single,register-width = <32>;
		};
	};
};
